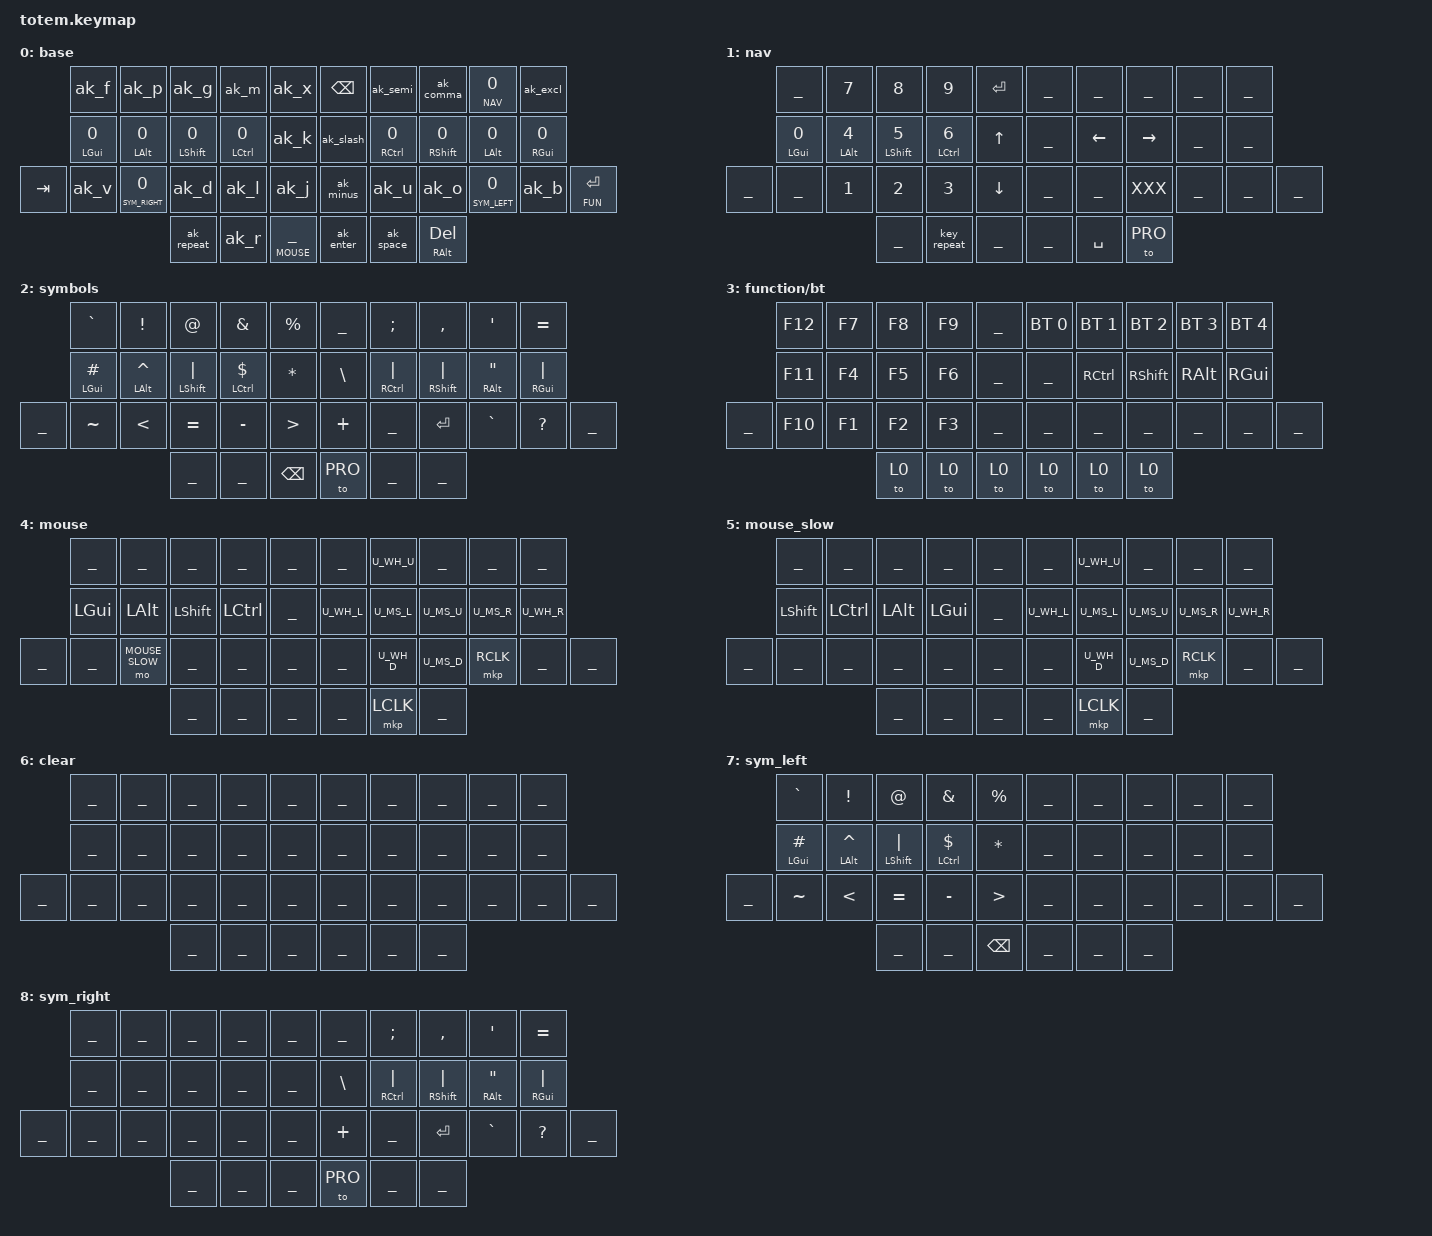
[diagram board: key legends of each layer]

//                                                        ▀▀▀▀▀     ▀▀▀▀▀          ▀▀█▀▀
//                                                        ▄▀▀▀▄  ▄  ▄▀▀▀▄  ▄  ▄▀▀▀▄  █  ▄▀▀▀▄
//                                                        █   █  █  █   █  █  █   █  █  █   █
//                                                         ▀▀▀   █   ▀▀▀   █   ▀▀▀   ▀   ▀▀▀
//                                                               █      ▄▄▄█▄▄▄    █   █  
//                                                               ▀      █  █  █     █▄█
//                                                             ▀▀▀▀▀    █  █  █      ▀
//                                                                      ▀  ▀  ▀
//
// ▄▄▄▄▄▄▄▄▄▄▄▄▄▄▄▄▄▄▄▄▄▄▄▄▄▄▄▄▄▄▄▄▄▄▄▄▄▄▄▄▄▄▄▄▄▄▄▄▄▄▄▄▄▄▄▄▄▄▄▄▄▄▄▄▄▄▄▄▄▄▄▄▄▄▄▄▄▄▄▄▄▄▄▄▄▄▄▄▄▄▄▄▄▄▄▄▄▄▄▄▄▄▄▄▄▄▄▄▄▄▄▄▄▄▄▄▄▄▄▄▄▄▄▄▄▄▄▄▄▄▄▄▄▄▄▄▄▄▄▄▄▄▄▄▄▄▄▄▄

#define LEFT_HAND_KEYS 0 1 2 3 4 10 11 12 13 14 20 21 22 23 24 25
#define RIGHT_HAND_KEYS 5 6 7 8 9 15 16 17 18 19 26 27 28 29 30 31
#define THUMBS 32 33 34 35 36 37
#define LEFT_LEFT_COLUMN 20

#define PRO 0
#define NAV 1
#define SYM 2
#define FUN 3
#define MOUSE 4
#define MOUSE_SLOW 5
#define SYM_LEFT 7
#define SYM_RIGHT 8

#include "totem_layout.h"

#include "bernelius/constants.dtsi"
#include <behaviors.dtsi>
#include <dt-bindings/zmk/bt.h>
#include <dt-bindings/zmk/keys.h>
#include "mouse.dtsi"

/ {
    behaviors {
        #include "bernelius/pm_adaptive_keys.dtsi"
        #include "bernelius/behaviors.dtsi"
    };

    combos {
        #include "bernelius/combos.dtsi"
    };

    macros {
        #include "bernelius/macros.dtsi"
    };


    keymap {
        compatible = "zmk,keymap";


      layer0  {
            display-name = "base";
            bindings = <
//                ╭──────0─────┬──────1────────┬───────2───────┬───────3────────┬─────4──────╮ ╭─────5──────┬───────6───────┬───────7───────┬───────8───────┬─────9─────╮
                   &ak_f        &ak_p           &ak_g           &ak_m            &ak_x          &kp BSPC     &ak_semi        &ak_comma       &lt_dot NAV 0   &ak_excl
//                ├─────10─────┼──────11───────┼───────12──────┼───────13───────┼─────14─────┤ ├────15──────┼──────16───────┼──────17───────┼──────18───────┼────19─────┤
                  &hml_s LGUI 0 &hml_n LALT 0   &hml_t LSHFT 0  &hml_h LCTRL 0   &ak_k          &ak_slash    &hmr_a RCTRL 0  &hmr_e RSHFT 0  &hmr_i LALT 0   &hmr_c RGUI 0       
//╭──────20───────┼─────21─────┼──────22───────┼───────23──────┼───────24───────┼─────25─────┤ ├────26──────┼──────27───────┼──────28───────┼──────29───────┼────30─────┼──────31───────╮
   &kp TAB         &ak_v        &lt_w SYM_RIGHT 0 &ak_d         &ak_l            &ak_j          &ak_minus    &ak_u           &ak_o           &lt_y SYM_LEFT 0 &ak_b      &lt FUN ENTER 
//╰───────────────┴────────────┴───────────────┼───────32──────┼───────33───────┼─────34─────┤ ├────35──────┼──────36───────┼──────37───────┼───────────────┴───────────┴───────────────╯
                                                &ak_repeat      &ak_r           &lt MOUSE UNDER &ak_enter    &ak_space       &mt RALT DELETE
//                                             ╰───────────────┴────────────────┴────────────╯ ╰────────────┴───────────────┴───────────────╯
                 >;
      };

      layer1 {
            display-name = "nav";
            bindings = <
//                ╭──────0─────┬──────1────────┬───────2───────┬───────3────────┬─────4──────╮ ╭─────5──────┬───────6───────┬───────7───────┬───────8───────┬─────9─────╮
                   ___          &kp N7          &kp N8          &kp N9           &kp ENTER      ___          ___             ___             ___             ___     
//                ├─────10─────┼──────11───────┼───────12──────┼───────13───────┼─────14─────┤ ├────15──────┼──────16───────┼──────17───────┼──────18───────┼────19─────┤
                  &hml LGUI N0  &hml LALT N4    &hml LSHFT N5   &hml LCTRL N6    &kp UP         ___          &kp LEFT        &kp RIGHT       ___             ___
//╭──────20───────┼─────21─────┼──────22───────┼───────23──────┼───────24───────┼─────25─────┤ ├────26──────┼──────27───────┼──────28───────┼──────29───────┼────30─────┼──────31───────╮
   ___             ___          &kp N1          &kp N2          &kp N3           &kp DOWN       ___          ___             XXX             ___             ___         ___
//╰───────────────┴────────────┴───────────────┼───────32──────┼───────33───────┼─────34─────┤ ├────35──────┼──────36───────┼──────37───────┼───────────────┴───────────┴───────────────╯
                                                ___             &key_repeat      ___            ___          &kp SPACE       &to PRO
//                                             ╰───────────────┴────────────────┴────────────╯ ╰────────────┴───────────────┴───────────────╯
              >;
        };

       
       layer2 {
            display-name = "symbols";
            bindings = <
//                ╭──────0─────┬──────1────────┬───────2───────┬───────3────────┬─────4──────╮ ╭─────5──────┬───────6───────┬───────7───────┬───────8───────┬─────9─────╮
                   &kp GRAVE    &kp EXCL        &kp AT          &kp AMPERSAND    &kp PERCENT    ___          &kp SEMI        &kp COMMA       &kp APOS        &kp EQUAL
//                ├─────10─────┼──────11───────┼───────12──────┼───────13───────┼─────14─────┤ ├────15──────┼──────16───────┼──────17───────┼──────18───────┼────19─────┤
                 &hml LGUI HASH &hml LALT CARET &hml LSHFT PIPE &hml LCTRL DLLR  &kp ASTERISK   &kp BSLH     &hmr RCTRL PIPE &hmr RSHFT PIPE &hmr RALT DQT   &hmr RGUI PIPE
//╭──────20───────┼─────21─────┼──────22───────┼───────23──────┼───────24───────┼─────25─────┤ ├────26──────┼──────27───────┼──────28───────┼──────29───────┼────30─────┼──────31───────╮
   ___             &kp TILDE    &kp LT          &kp EQUAL       &kp MINUS        &kp GT         &kp PLUS     ___             &kp ENTER       &kp GRAVE       &kp QMARK   ___
//╰───────────────┴────────────┴───────────────┼───────32──────┼───────33───────┼─────34─────┤ ├────35──────┼──────36───────┼──────37───────┼───────────────┴───────────┴───────────────╯
                                                ___             ___              &kp BSPC       &to PRO      ___             ___         
//                                             ╰───────────────┴────────────────┴────────────╯ ╰────────────┴───────────────┴───────────────╯
            >;
        };


        layer3 {
            display-name = "function/bt";
            bindings = <
//                ╭──────0─────┬──────1────────┬───────2───────┬───────3────────┬─────4──────╮ ╭─────5──────┬───────6───────┬───────7───────┬───────8───────┬─────9─────╮
                   &kp F12      &kp F7          &kp F8          &kp F9           ___            &bt BT_SEL 0 &bt BT_SEL 1    &bt BT_SEL 2    &bt BT_SEL 3    &bt BT_SEL 4
//                ├─────10─────┼──────11───────┼───────12──────┼───────13───────┼─────14─────┤ ├────15──────┼──────16───────┼──────17───────┼──────18───────┼────19─────┤
                   &kp F11      &kp F4          &kp F5          &kp F6           ___            ___          &kp RCTRL       &kp RSHFT       &kp RALT        &kp RGUI
//╭──────20───────┼─────21─────┼──────22───────┼───────23──────┼───────24───────┼─────25─────┤ ├────26──────┼──────27───────┼──────28───────┼──────29───────┼────30─────┼──────31───────╮
   ___             &kp F10      &kp F1          &kp F2          &kp F3           ___            ___          ___             ___             ___             ___         ___          
//╰───────────────┴────────────┴───────────────┼───────32──────┼───────33───────┼─────34─────┤ ├────35──────┼──────36───────┼──────37───────┼───────────────┴───────────┴───────────────╯
                                                &to 0           &to 0            &to 0          &to 0        &to 0           &to 0       
//                                             ╰───────────────┴────────────────┴────────────╯ ╰────────────┴───────────────┴───────────────╯
            >;

        };

       layer4 {
            display-name = "mouse";
            bindings = <
//                ╭──────0─────┬──────1────────┬───────2───────┬───────3────────┬─────4──────╮ ╭─────5──────┬───────6───────┬───────7───────┬───────8───────┬─────9─────╮
                   ___          ___             ___             ___              ___            ___          U_WH_U          ___             ___             ___ 
//                ├─────10─────┼──────11───────┼───────12──────┼───────13───────┼─────14─────┤ ├────15──────┼──────16───────┼──────17───────┼──────18───────┼────19─────┤
                   &kp LGUI     &kp LALT        &kp LSHFT       &kp LCTRL        ___            U_WH_L       U_MS_L          U_MS_U          U_MS_R          U_WH_R
//╭──────20───────┼─────21─────┼──────22───────┼───────23──────┼───────24───────┼─────25─────┤ ├────26──────┼──────27───────┼──────28───────┼──────29───────┼────30─────┼──────31───────╮
   ___             ___          &mo MOUSE_SLOW  ___             ___              ___            ___          U_WH_D          U_MS_D          &mkp RCLK       ___         ___
//╰───────────────┴────────────┴───────────────┼───────32──────┼───────33───────┼─────34─────┤ ├────35──────┼──────36───────┼──────37───────┼───────────────┴───────────┴───────────────╯
                                                ___             ___              ___            ___          &mkp LCLK       ___         
//                                             ╰───────────────┴────────────────┴────────────╯ ╰────────────┴───────────────┴───────────────╯
                    >;
            };

       layer5 {
            display-name = "mouse_slow";
            bindings = <
//                ╭──────0─────┬──────1────────┬───────2───────┬───────3────────┬─────4──────╮ ╭─────5──────┬───────6───────┬───────7───────┬───────8───────┬─────9─────╮
                   ___          ___             ___             ___              ___            ___          U_WH_U          ___             ___             ___ 
//                ├─────10─────┼──────11───────┼───────12──────┼───────13───────┼─────14─────┤ ├────15──────┼──────16───────┼──────17───────┼──────18───────┼────19─────┤
                   &kp LSHIFT   &kp LCTRL       &kp LALT        &kp LGUI         ___            U_WH_L       U_MS_L          U_MS_U          U_MS_R          U_WH_R
//╭──────20───────┼─────21─────┼──────22───────┼───────23──────┼───────24───────┼─────25─────┤ ├────26──────┼──────27───────┼──────28───────┼──────29───────┼────30─────┼──────31───────╮
   ___             ___          ___             ___             ___              ___            ___          U_WH_D          U_MS_D          &mkp RCLK       ___         ___
//╰───────────────┴────────────┴───────────────┼───────32──────┼───────33───────┼─────34─────┤ ├────35──────┼──────36───────┼──────37───────┼───────────────┴───────────┴───────────────╯
                                                ___             ___              ___            ___          &mkp LCLK       ___         
//                                             ╰───────────────┴────────────────┴────────────╯ ╰────────────┴───────────────┴───────────────╯
                    >;
            };

      layer6 {
            display-name = "clear";
            bindings = <
//                ╭──────0─────┬──────1────────┬───────2───────┬───────3────────┬─────4──────╮ ╭─────5──────┬───────6───────┬───────7───────┬───────8───────┬─────9─────╮
                   ___          ___             ___             ___              ___            ___          ___             ___             ___             ___ 
//                ├─────10─────┼──────11───────┼───────12──────┼───────13───────┼─────14─────┤ ├────15──────┼──────16───────┼──────17───────┼──────18───────┼────19─────┤
                   ___          ___             ___             ___              ___            ___          ___             ___             ___             ___
//╭──────20───────┼─────21─────┼──────22───────┼───────23──────┼───────24───────┼─────25─────┤ ├────26──────┼──────27───────┼──────28───────┼──────29───────┼────30─────┼──────31───────╮
   ___             ___          ___             ___             ___              ___            ___          ___             ___             ___             ___         ___
//╰───────────────┴────────────┴───────────────┼───────32──────┼───────33───────┼─────34─────┤ ├────35──────┼──────36───────┼──────37───────┼───────────────┴───────────┴───────────────╯
                                                ___             ___              ___            ___          ___             ___         
//                                             ╰───────────────┴────────────────┴────────────╯ ╰────────────┴───────────────┴───────────────╯
                    >;
            };

        layer7 {
              display-name = "sym_left";
              bindings = <
  //                ╭──────0─────┬──────1────────┬───────2───────┬───────3────────┬─────4──────╮ ╭─────5──────┬───────6───────┬───────7───────┬───────8───────┬─────9─────╮
                     &kp GRAVE    &kp EXCL        &kp AT          &kp AMPERSAND    &kp PERCENT    ___          ___             ___             ___             ___        
  //                ├─────10─────┼──────11───────┼───────12──────┼───────13───────┼─────14─────┤ ├────15──────┼──────16───────┼──────17───────┼──────18───────┼────19─────┤
                   &hml LGUI HASH &hml LALT CARET &hml LSHFT PIPE &hml LCTRL DLLR  &kp ASTERISK   ___          ___             ___             ___             ___       
  //╭──────20───────┼─────21─────┼──────22───────┼───────23──────┼───────24───────┼─────25─────┤ ├────26──────┼──────27───────┼──────28───────┼──────29───────┼────30─────┼──────31───────╮
     ___             &kp TILDE    &kp LT          &kp EQUAL       &kp MINUS        &kp GT         ___          ___             ___             ___             ___         ___
  //╰───────────────┴────────────┴───────────────┼───────32──────┼───────33───────┼─────34─────┤ ├────35──────┼──────36───────┼──────37───────┼───────────────┴───────────┴───────────────╯
                                                  ___             ___              &kp BSPC       ___          ___             ___         
  //                                             ╰───────────────┴────────────────┴────────────╯ ╰────────────┴───────────────┴───────────────╯
                      >;
              };

        layer8 {
              display-name = "sym_right";
              bindings = <
  //                ╭──────0─────┬──────1────────┬───────2───────┬───────3────────┬─────4──────╮ ╭─────5──────┬───────6───────┬───────7───────┬───────8───────┬─────9─────╮
                     ___          ___             ___             ___              ___            ___          &kp SEMI        &kp COMMA       &kp APOS        &kp EQUAL
  //                ├─────10─────┼──────11───────┼───────12──────┼───────13───────┼─────14─────┤ ├────15──────┼──────16───────┼──────17───────┼──────18───────┼────19─────┤
                     ___          ___             ___             ___              ___            &kp BSLH     &hmr RCTRL PIPE &hmr RSHFT PIPE &hmr RALT DQT   &hmr RGUI PIPE
  //╭──────20───────┼─────21─────┼──────22───────┼───────23──────┼───────24───────┼─────25─────┤ ├────26──────┼──────27───────┼──────28───────┼──────29───────┼────30─────┼──────31───────╮
     ___             ___          ___             ___             ___              ___            &kp PLUS     ___             &kp ENTER       &kp GRAVE       &kp QMARK   ___
  //╰───────────────┴────────────┴───────────────┼───────32──────┼───────33───────┼─────34─────┤ ├────35──────┼──────36───────┼──────37───────┼───────────────┴───────────┴───────────────╯
                                                  ___             ___              ___            &to PRO      ___             ___         
  //                                             ╰───────────────┴────────────────┴────────────╯ ╰────────────┴───────────────┴───────────────╯
                      >;
              };

        layer9 { status = "reserved"; };
        
    };
};
